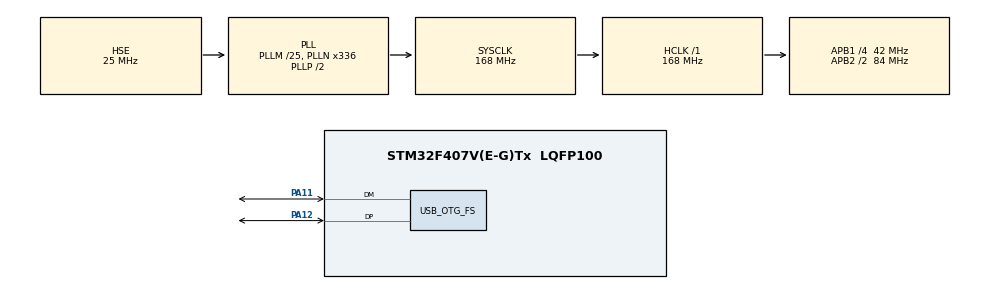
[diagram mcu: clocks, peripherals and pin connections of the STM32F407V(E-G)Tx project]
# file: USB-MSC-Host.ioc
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FATFS._CODE_PAGE=437
FATFS._USE_LFN=1
Mcu.Family=STM32F4
Mcu.Name=STM32F407V(E-G)Tx
Mcu.Package=LQFP100
NVIC.OTG_FS_IRQn=true\:0\:0\:false\:false\:true\:true\:true
NVIC.PriorityGroup=NVIC_PRIORITYGROUP_4
PA11.Mode=Host_Only
PA11.Signal=USB_OTG_FS_DM
PA12.Mode=Host_Only
PA12.Signal=USB_OTG_FS_DP
PH0-OSC_IN.Mode=HSE-External-Oscillator
PH0-OSC_IN.Signal=RCC_OSC_IN
PH1-OSC_OUT.Mode=HSE-External-Oscillator
PH1-OSC_OUT.Signal=RCC_OSC_OUT
ProjectManager.HeapSize=0x200
ProjectManager.StackSize=0x400
ProjectManager.TargetToolchain=MDK-ARM V5.27
RCC.48MHZClocksFreq_Value=48000000
RCC.AHBFreq_Value=168000000
RCC.APB1CLKDivider=RCC_HCLK_DIV4
RCC.APB1Freq_Value=42000000
RCC.APB1TimFreq_Value=84000000
RCC.APB2CLKDivider=RCC_HCLK_DIV2
RCC.APB2Freq_Value=84000000
RCC.APB2TimFreq_Value=168000000
RCC.CortexFreq_Value=168000000
RCC.HCLKFreq_Value=168000000
RCC.HSE_VALUE=25000000
RCC.HSI_VALUE=16000000
RCC.LSE_VALUE=32768
RCC.PLLM=25
RCC.PLLN=336
RCC.PLLQ=7
RCC.SYSCLKFreq_VALUE=168000000
RCC.SYSCLKSource=RCC_SYSCLKSOURCE_PLLCLK
RCC.VCOOutputFreq_Value=336000000
USB_HOST.USBH_HandleTypeDef-MSC_FS=hUsbHostFS
USB_HOST.VirtualModeFS=Msc
USB_OTG_FS.VirtualMode=Host_Only
USB_OTG_FS.phy_itface=HCD_PHY_EMBEDDED
VP_FATFS_VS_USB.Mode=USB
VP_USB_HOST_VS_USB_HOST_MSC_FS.Mode=MSC_FS
board=custom

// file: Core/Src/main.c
/* USER CODE BEGIN Header */
/**
  ******************************************************************************
  * @file           : main.c
  * @brief          : Main program body
  ******************************************************************************
  * @attention
  *
  * <h2><center>&copy; Copyright (c) 2024 STMicroelectronics.
  * All rights reserved.</center></h2>
  *
  * This software component is licensed by ST under Ultimate Liberty license
  * SLA0044, the "License"; You may not use this file except in compliance with
  * the License. You may obtain a copy of the License at:
  *                             www.st.com/SLA0044
  *
  ******************************************************************************
  */
/* USER CODE END Header */
#include "main.h"
#include "fatfs.h"
#include "usb_host.h"
#include "gpio.h"

/* USER CODE BEGIN Includes */
#include "ALCD.h"
/* USER CODE END Includes */

/* USER CODE BEGIN PV */
static const char STARTUP_PATH[]   = "Startup.txt";
static const char TEMPLATE[]       = "Hello from Nira Board";

static const char ALCD_TEXT_PATH[] = "alcd.txt";

uint8_t creatFileFlag = 0;
uint8_t readAlcdFileFlag = 0;
/* USER CODE END PV */

void SystemClock_Config(void);
void MX_USB_HOST_Process(void);

int main(void)
{

  /* MCU Configuration--------------------------------------------------------*/

  /* Reset of all peripherals, Initializes the Flash interface and the Systick. */
  HAL_Init();

  /* Configure the system clock */
  SystemClock_Config();

  /* Initialize all configured peripherals */
  MX_GPIO_Init();
  MX_FATFS_Init();
  MX_USB_HOST_Init();
  /* USER CODE BEGIN 2 */
  ALCD_init(16, 2);
  ALCD_clear();
  /* USER CODE END 2 */

  /* Infinite loop */
  while (1)
  {
    MX_USB_HOST_Process();

    /* USER CODE BEGIN 3 */
    if (USBHFatFS.fs_type != 0) {
      if (creatFileFlag) {
        creatFileFlag = 0;
        // Creat File
        if (f_open(&USBHFile, STARTUP_PATH, FA_CREATE_ALWAYS | FA_WRITE) == FR_OK) {
          uint32_t writeCount;

          f_write(&USBHFile, TEMPLATE, sizeof(TEMPLATE) - 1, &writeCount);
          while (writeCount < sizeof(TEMPLATE) - 1);

          f_close(&USBHFile);
        }
      }

      if (readAlcdFileFlag) {
        readAlcdFileFlag = 0;
        // Open File
        if (f_open(&USBHFile, ALCD_TEXT_PATH, FA_OPEN_EXISTING | FA_READ) == FR_OK) {
          char buff[33];
          uint32_t readCount;

          f_read(&USBHFile, buff, sizeof(buff) - 1, &readCount);
          while (readCount < sizeof(TEMPLATE) - 1 && readCount < f_size(&USBHFile));

          buff[readCount] = '\0';
          ALCD_putsXY(0, 0, buff);

          f_close(&USBHFile);
        }
      }
    }
  }
  /* USER CODE END 3 */
}

void SystemClock_Config(void)
{
  RCC_OscInitTypeDef RCC_OscInitStruct = {0};
  RCC_ClkInitTypeDef RCC_ClkInitStruct = {0};

  /** Configure the main internal regulator output voltage
  */
  __HAL_RCC_PWR_CLK_ENABLE();
  __HAL_PWR_VOLTAGESCALING_CONFIG(PWR_REGULATOR_VOLTAGE_SCALE1);
  /** Initializes the RCC Oscillators according to the specified parameters
  * in the RCC_OscInitTypeDef structure.
  */
  RCC_OscInitStruct.OscillatorType = RCC_OSCILLATORTYPE_HSE;
  RCC_OscInitStruct.HSEState = RCC_HSE_ON;
  RCC_OscInitStruct.PLL.PLLState = RCC_PLL_ON;
  RCC_OscInitStruct.PLL.PLLSource = RCC_PLLSOURCE_HSE;
  RCC_OscInitStruct.PLL.PLLM = 25;
  RCC_OscInitStruct.PLL.PLLN = 336;
  RCC_OscInitStruct.PLL.PLLP = RCC_PLLP_DIV2;
  RCC_OscInitStruct.PLL.PLLQ = 7;
  if (HAL_RCC_OscConfig(&RCC_OscInitStruct) != HAL_OK)
  {
    Error_Handler();
  }
  /** Initializes the CPU, AHB and APB buses clocks
  */
  RCC_ClkInitStruct.ClockType = RCC_CLOCKTYPE_HCLK|RCC_CLOCKTYPE_SYSCLK
                              |RCC_CLOCKTYPE_PCLK1|RCC_CLOCKTYPE_PCLK2;
  RCC_ClkInitStruct.SYSCLKSource = RCC_SYSCLKSOURCE_PLLCLK;
  RCC_ClkInitStruct.AHBCLKDivider = RCC_SYSCLK_DIV1;
  RCC_ClkInitStruct.APB1CLKDivider = RCC_HCLK_DIV4;
  RCC_ClkInitStruct.APB2CLKDivider = RCC_HCLK_DIV2;

  if (HAL_RCC_ClockConfig(&RCC_ClkInitStruct, FLASH_LATENCY_5) != HAL_OK)
  {
    Error_Handler();
  }
}

/* USER CODE BEGIN 4 */
void MSC_OnConnect(void) {
  f_mount(&USBHFatFS, USBHPath, 1);
  creatFileFlag = 1;
  readAlcdFileFlag  = 1;
}
void MSC_OnDisconnect(void) {
  f_mount(&USBHFatFS, NULL, 0);
}
/* USER CODE END 4 */

void Error_Handler(void)
{
  __disable_irq();
  while (1)
  {
  }
}

/************************ (C) COPYRIGHT STMicroelectronics *****END OF FILE****/
